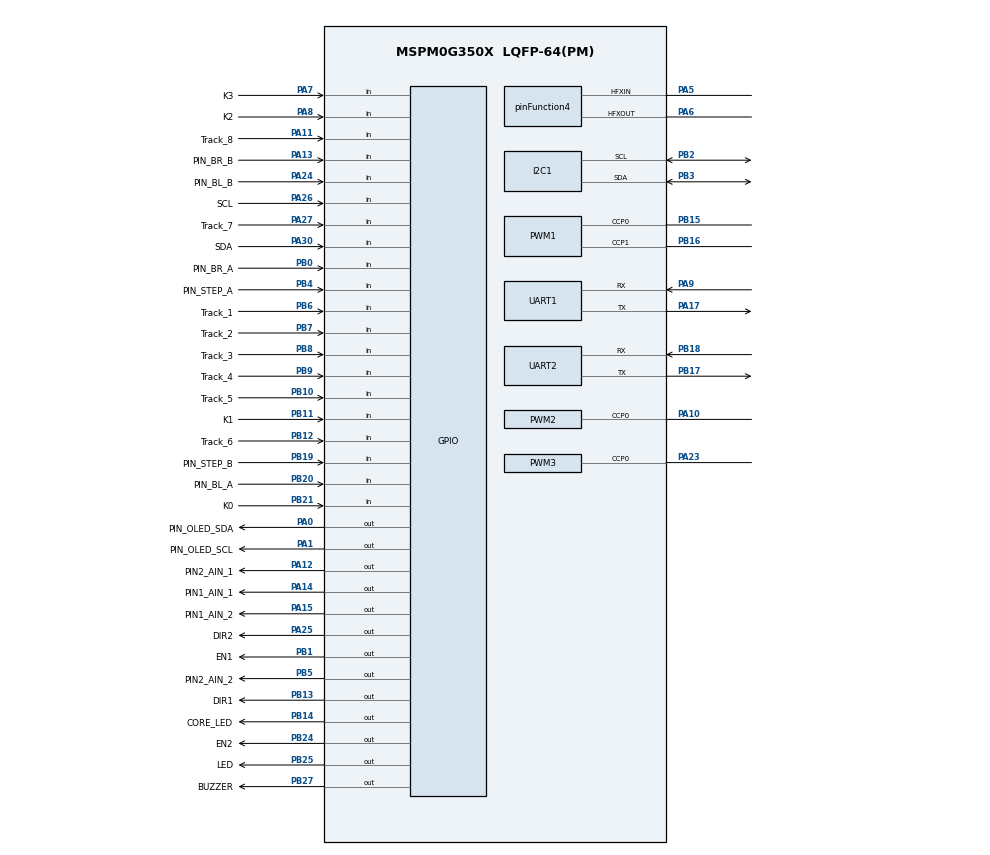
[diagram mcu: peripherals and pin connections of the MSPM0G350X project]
/**
 *
 * @cliArgs --device "MSPM0G350X" --part "Default" --package "LQFP-64(PM)" --product "mspm0_sdk@2.11.00.07"
 * @versions {"tool":"1.28.0+4696"}
 */

/**
 * Import the modules used in this configuration.
 */
const GPIO          = scripting.addModule("/ti/driverlib/GPIO", {}, false);
const GPIO1         = GPIO.addInstance();
const GPIO2         = GPIO.addInstance();
const GPIO3         = GPIO.addInstance();
const GPIO4         = GPIO.addInstance();
const GPIO5         = GPIO.addInstance();
const GPIO6         = GPIO.addInstance();
const GPIO7         = GPIO.addInstance();
const GPIO8         = GPIO.addInstance();
const GPIO9         = GPIO.addInstance();
const GPIO10        = GPIO.addInstance();
const GPIO11        = GPIO.addInstance();
const GPIO12        = GPIO.addInstance();
const I2C           = scripting.addModule("/ti/driverlib/I2C", {}, false);
const I2C1          = I2C.addInstance();
const PWM           = scripting.addModule("/ti/driverlib/PWM", {}, false);
const PWM1          = PWM.addInstance();
const PWM2          = PWM.addInstance();
const PWM3          = PWM.addInstance();
const SYSCTL        = scripting.addModule("/ti/driverlib/SYSCTL");
const SYSTICK       = scripting.addModule("/ti/driverlib/SYSTICK");
const TIMER         = scripting.addModule("/ti/driverlib/TIMER", {}, false);
const TIMER1        = TIMER.addInstance();
const TIMER2        = TIMER.addInstance();
const TIMER3        = TIMER.addInstance();
const UART          = scripting.addModule("/ti/driverlib/UART", {}, false);
const UART1         = UART.addInstance();
const UART2         = UART.addInstance();
const ProjectConfig = scripting.addModule("/ti/project_config/ProjectConfig");

/**
 * Write custom configuration values to the imported modules.
 */
const divider6       = system.clockTree["PLL_CLK2X_DIV"];
divider6.divideValue = 4;

const divider7       = system.clockTree["PLL_PDIV"];
divider7.divideValue = 2;

const divider9       = system.clockTree["UDIV"];
divider9.divideValue = 2;

const multiplier2         = system.clockTree["PLL_QDIV"];
multiplier2.multiplyValue = 8;

const mux4       = system.clockTree["EXHFMUX"];
mux4.inputSelect = "EXHFMUX_XTAL";

const mux8       = system.clockTree["HSCLKMUX"];
mux8.inputSelect = "HSCLKMUX_SYSPLL2X";

const mux12       = system.clockTree["SYSPLLMUX"];
mux12.inputSelect = "zSYSPLLMUX_HFCLK";

const pinFunction4                        = system.clockTree["HFXT"];
pinFunction4.enable                       = true;
pinFunction4.inputFreq                    = 40;
pinFunction4.HFXTStartup                  = 10;
pinFunction4.HFCLKMonitor                 = true;
pinFunction4.peripheral.hfxInPin.$assign  = "PA5";
pinFunction4.peripheral.hfxOutPin.$assign = "PA6";

GPIO1.$name                         = "GPIO_CORE_LED";
GPIO1.associatedPins[0].$name       = "CORE_LED";
GPIO1.associatedPins[0].pin.$assign = "PB14";

const Board = scripting.addModule("/ti/driverlib/Board", {}, false);

GPIO2.$name                         = "GPIO_OLED";
GPIO2.associatedPins.create(2);
GPIO2.associatedPins[0].$name       = "PIN_OLED_SCL";
GPIO2.associatedPins[0].pin.$assign = "PA1";
GPIO2.associatedPins[1].$name       = "PIN_OLED_SDA";
GPIO2.associatedPins[1].pin.$assign = "PA0";

GPIO3.$name                              = "GPIO_KEYS";
GPIO3.associatedPins.create(4);
GPIO3.associatedPins[0].$name            = "K0";
GPIO3.associatedPins[0].direction        = "INPUT";
GPIO3.associatedPins[0].internalResistor = "PULL_UP";
GPIO3.associatedPins[0].pin.$assign      = "PB21";
GPIO3.associatedPins[1].$name            = "K1";
GPIO3.associatedPins[1].direction        = "INPUT";
GPIO3.associatedPins[1].internalResistor = "PULL_UP";
GPIO3.associatedPins[1].pin.$assign      = "PB11";
GPIO3.associatedPins[2].$name            = "K2";
GPIO3.associatedPins[2].direction        = "INPUT";
GPIO3.associatedPins[2].internalResistor = "PULL_UP";
GPIO3.associatedPins[2].pin.$assign      = "PA8";
GPIO3.associatedPins[3].$name            = "K3";
GPIO3.associatedPins[3].direction        = "INPUT";
GPIO3.associatedPins[3].internalResistor = "PULL_UP";
GPIO3.associatedPins[3].pin.$assign      = "PA7";

GPIO4.$name                         = "GPIO_LED_BUZZER";
GPIO4.associatedPins.create(2);
GPIO4.associatedPins[0].$name       = "LED";
GPIO4.associatedPins[0].pin.$assign = "PB25";
GPIO4.associatedPins[1].$name       = "BUZZER";
GPIO4.associatedPins[1].pin.$assign = "PB27";

GPIO5.$name                         = "GPIO_AT24";
GPIO5.associatedPins.create(2);
GPIO5.associatedPins[0].$name       = "SCL";
GPIO5.associatedPins[0].direction   = "INPUT";
GPIO5.associatedPins[0].pin.$assign = "PA26";
GPIO5.associatedPins[1].$name       = "SDA";
GPIO5.associatedPins[1].direction   = "INPUT";
GPIO5.associatedPins[1].pin.$assign = "PA30";

GPIO6.$name                         = "GPIO_MOTOR_1";
GPIO6.associatedPins.create(2);
GPIO6.associatedPins[0].$name       = "PIN1_AIN_1";
GPIO6.associatedPins[0].pin.$assign = "PA14";
GPIO6.associatedPins[1].$name       = "PIN1_AIN_2";
GPIO6.associatedPins[1].pin.$assign = "PA15";

GPIO7.$name                         = "GPIO_MOTOR_2";
GPIO7.associatedPins.create(2);
GPIO7.associatedPins[0].$name       = "PIN2_AIN_1";
GPIO7.associatedPins[0].pin.$assign = "PA12";
GPIO7.associatedPins[1].$name       = "PIN2_AIN_2";
GPIO7.associatedPins[1].pin.$assign = "PB5";

GPIO8.$name                         = "GPIO_ENCODER_BL";
GPIO8.associatedPins.create(2);
GPIO8.associatedPins[0].$name       = "PIN_BL_A";
GPIO8.associatedPins[0].direction   = "INPUT";
GPIO8.associatedPins[0].interruptEn = true;
GPIO8.associatedPins[0].polarity    = "RISE";
GPIO8.associatedPins[0].pin.$assign = "PB20";
GPIO8.associatedPins[1].$name       = "PIN_BL_B";
GPIO8.associatedPins[1].direction   = "INPUT";
GPIO8.associatedPins[1].pin.$assign = "PA24";

GPIO9.$name                         = "GPIO_ENCODER_BR";
GPIO9.associatedPins.create(2);
GPIO9.associatedPins[0].$name       = "PIN_BR_A";
GPIO9.associatedPins[0].direction   = "INPUT";
GPIO9.associatedPins[0].interruptEn = true;
GPIO9.associatedPins[0].polarity    = "RISE";
GPIO9.associatedPins[0].pin.$assign = "PB0";
GPIO9.associatedPins[1].$name       = "PIN_BR_B";
GPIO9.associatedPins[1].direction   = "INPUT";
GPIO9.associatedPins[1].pin.$assign = "PA13";

GPIO10.$name                         = "GPIO_STEP_MOTOR";
GPIO10.associatedPins.create(4);
GPIO10.associatedPins[0].$name       = "DIR1";
GPIO10.associatedPins[0].pin.$assign = "PB13";
GPIO10.associatedPins[1].$name       = "DIR2";
GPIO10.associatedPins[1].pin.$assign = "PA25";
GPIO10.associatedPins[2].$name       = "EN1";
GPIO10.associatedPins[2].pin.$assign = "PB1";
GPIO10.associatedPins[3].$name       = "EN2";
GPIO10.associatedPins[3].pin.$assign = "PB24";

GPIO11.$name                              = "GPIO_Track";
GPIO11.associatedPins.create(8);
GPIO11.associatedPins[0].$name            = "Track_1";
GPIO11.associatedPins[0].direction        = "INPUT";
GPIO11.associatedPins[0].internalResistor = "PULL_UP";
GPIO11.associatedPins[0].pin.$assign      = "PB6";
GPIO11.associatedPins[1].$name            = "Track_2";
GPIO11.associatedPins[1].direction        = "INPUT";
GPIO11.associatedPins[1].internalResistor = "PULL_UP";
GPIO11.associatedPins[1].pin.$assign      = "PB7";
GPIO11.associatedPins[2].$name            = "Track_3";
GPIO11.associatedPins[2].direction        = "INPUT";
GPIO11.associatedPins[2].internalResistor = "PULL_UP";
GPIO11.associatedPins[2].pin.$assign      = "PB8";
GPIO11.associatedPins[3].$name            = "Track_4";
GPIO11.associatedPins[3].direction        = "INPUT";
GPIO11.associatedPins[3].internalResistor = "PULL_UP";
GPIO11.associatedPins[3].pin.$assign      = "PB9";
GPIO11.associatedPins[4].$name            = "Track_5";
GPIO11.associatedPins[4].direction        = "INPUT";
GPIO11.associatedPins[4].internalResistor = "PULL_UP";
GPIO11.associatedPins[4].pin.$assign      = "PB10";
GPIO11.associatedPins[5].$name            = "Track_6";
GPIO11.associatedPins[5].direction        = "INPUT";
GPIO11.associatedPins[5].internalResistor = "PULL_UP";
GPIO11.associatedPins[5].pin.$assign      = "PB12";
GPIO11.associatedPins[6].$name            = "Track_7";
GPIO11.associatedPins[6].direction        = "INPUT";
GPIO11.associatedPins[6].internalResistor = "PULL_UP";
GPIO11.associatedPins[6].pin.$assign      = "PA27";
GPIO11.associatedPins[7].$name            = "Track_8";
GPIO11.associatedPins[7].direction        = "INPUT";
GPIO11.associatedPins[7].internalResistor = "PULL_UP";
GPIO11.associatedPins[7].pin.$assign      = "PA11";

GPIO12.$name                         = "GPIO_ENCODER_STEP";
GPIO12.associatedPins.create(2);
GPIO12.associatedPins[0].$name       = "PIN_STEP_A";
GPIO12.associatedPins[0].direction   = "INPUT";
GPIO12.associatedPins[0].interruptEn = true;
GPIO12.associatedPins[0].polarity    = "RISE";
GPIO12.associatedPins[0].pin.$assign = "PB4";
GPIO12.associatedPins[1].$name       = "PIN_STEP_B";
GPIO12.associatedPins[1].direction   = "INPUT";
GPIO12.associatedPins[1].pin.$assign = "PB19";

I2C1.$name                             = "I2C_IMU";
I2C1.basicEnableController             = true;
I2C1.basicControllerStandardBusSpeed   = "Fast";
I2C1.peripheral.$assign                = "I2C1";
I2C1.peripheral.sdaPin.$assign         = "PB3";
I2C1.peripheral.sclPin.$assign         = "PB2";
I2C1.sdaPinConfig.$name                = "ti_driverlib_gpio_GPIOPinGeneric0";
I2C1.sdaPinConfig.hideOutputInversion  = scripting.forceWrite(false);
I2C1.sdaPinConfig.onlyInternalResistor = scripting.forceWrite(false);
I2C1.sdaPinConfig.passedPeripheralType = scripting.forceWrite("Digital");
I2C1.sclPinConfig.$name                = "ti_driverlib_gpio_GPIOPinGeneric1";
I2C1.sclPinConfig.hideOutputInversion  = scripting.forceWrite(false);
I2C1.sclPinConfig.onlyInternalResistor = scripting.forceWrite(false);
I2C1.sclPinConfig.passedPeripheralType = scripting.forceWrite("Digital");

PWM1.$name                              = "PWM_MOTOR";
PWM1.pwmMode                            = "EDGE_ALIGN_UP";
PWM1.peripheral.$assign                 = "TIMG8";
PWM1.peripheral.ccp0Pin.$assign         = "PB15";
PWM1.peripheral.ccp1Pin.$assign         = "PB16";
PWM1.PWM_CHANNEL_0.$name                = "ti_driverlib_pwm_PWMTimerCC1";
PWM1.PWM_CHANNEL_1.$name                = "ti_driverlib_pwm_PWMTimerCC0";
PWM1.ccp0PinConfig.direction            = scripting.forceWrite("OUTPUT");
PWM1.ccp0PinConfig.hideOutputInversion  = scripting.forceWrite(false);
PWM1.ccp0PinConfig.onlyInternalResistor = scripting.forceWrite(false);
PWM1.ccp0PinConfig.passedPeripheralType = scripting.forceWrite("Digital");
PWM1.ccp0PinConfig.$name                = "ti_driverlib_gpio_GPIOPinGeneric7";
PWM1.ccp1PinConfig.direction            = scripting.forceWrite("OUTPUT");
PWM1.ccp1PinConfig.hideOutputInversion  = scripting.forceWrite(false);
PWM1.ccp1PinConfig.onlyInternalResistor = scripting.forceWrite(false);
PWM1.ccp1PinConfig.passedPeripheralType = scripting.forceWrite("Digital");
PWM1.ccp1PinConfig.$name                = "ti_driverlib_gpio_GPIOPinGeneric6";

PWM2.$name                              = "STEP_MOTOR_1";
PWM2.clockPrescale                      = 8;
PWM2.timerCount                         = 5000;
PWM2.timerStartTimer                    = true;
PWM2.ccIndex                            = [0];
PWM2.interrupts                         = ["CC0_DN_EVENT"];
PWM2.PWM_CHANNEL_0.$name                = "ti_driverlib_pwm_PWMTimerCC2";
PWM2.ccp0PinConfig.direction            = scripting.forceWrite("OUTPUT");
PWM2.ccp0PinConfig.hideOutputInversion  = scripting.forceWrite(false);
PWM2.ccp0PinConfig.onlyInternalResistor = scripting.forceWrite(false);
PWM2.ccp0PinConfig.passedPeripheralType = scripting.forceWrite("Digital");
PWM2.ccp0PinConfig.$name                = "ti_driverlib_gpio_GPIOPinGeneric8";
PWM2.peripheral.$assign                 = "TIMA1";
PWM2.peripheral.ccp0Pin.$assign         = "PA10";

PWM3.$name                              = "STEP_MOTOR_2";
PWM3.clockPrescale                      = 8;
PWM3.timerCount                         = 5000;
PWM3.timerStartTimer                    = true;
PWM3.ccIndex                            = [0];
PWM3.interrupts                         = ["CC0_DN_EVENT"];
PWM3.PWM_CHANNEL_0.$name                = "ti_driverlib_pwm_PWMTimerCC3";
PWM3.ccp0PinConfig.direction            = scripting.forceWrite("OUTPUT");
PWM3.ccp0PinConfig.hideOutputInversion  = scripting.forceWrite(false);
PWM3.ccp0PinConfig.onlyInternalResistor = scripting.forceWrite(false);
PWM3.ccp0PinConfig.passedPeripheralType = scripting.forceWrite("Digital");
PWM3.ccp0PinConfig.$name                = "ti_driverlib_gpio_GPIOPinGeneric9";
PWM3.peripheral.$assign                 = "TIMG7";
PWM3.peripheral.ccp0Pin.$assign         = "PA23";

SYSCTL.forceDefaultClkConfig = true;
SYSCTL.clockTreeEn           = true;

SYSTICK.periodEnable    = true;
SYSTICK.interruptEnable = true;
SYSTICK.systickEnable   = true;
SYSTICK.period          = 80000;

TIMER1.$name              = "TIMER_ATT";
TIMER1.timerMode          = "PERIODIC";
TIMER1.timerPeriod        = "5 ms";
TIMER1.timerClkPrescale   = 8;
TIMER1.interrupts         = ["ZERO"];
TIMER1.interruptPriority  = "2";
TIMER1.peripheral.$assign = "TIMG0";

TIMER2.$name              = "TIMER_0";
TIMER2.timerMode          = "PERIODIC";
TIMER2.timerPeriod        = "10 ms";
TIMER2.timerClkPrescale   = 100;
TIMER2.interrupts         = ["ZERO"];
TIMER2.interruptPriority  = "1";
TIMER2.peripheral.$assign = "TIMA0";

TIMER3.$name              = "TIMER_BALL";
TIMER3.timerClkPrescale   = 100;
TIMER3.timerMode          = "PERIODIC";
TIMER3.timerPeriod        = "10 ms";
TIMER3.interrupts         = ["ZERO"];
TIMER3.interruptPriority  = "2";
TIMER3.peripheral.$assign = "TIMG6";

UART1.$name                            = "UART_Cam";
UART1.targetBaudRate                   = 115200;
UART1.enabledInterrupts                = ["RX"];
UART1.peripheral.$assign               = "UART1";
UART1.peripheral.rxPin.$assign         = "PA9";
UART1.peripheral.txPin.$assign         = "PA17";
UART1.txPinConfig.direction            = scripting.forceWrite("OUTPUT");
UART1.txPinConfig.hideOutputInversion  = scripting.forceWrite(false);
UART1.txPinConfig.onlyInternalResistor = scripting.forceWrite(false);
UART1.txPinConfig.passedPeripheralType = scripting.forceWrite("Digital");
UART1.txPinConfig.$name                = "ti_driverlib_gpio_GPIOPinGeneric2";
UART1.rxPinConfig.hideOutputInversion  = scripting.forceWrite(false);
UART1.rxPinConfig.onlyInternalResistor = scripting.forceWrite(false);
UART1.rxPinConfig.passedPeripheralType = scripting.forceWrite("Digital");
UART1.rxPinConfig.$name                = "ti_driverlib_gpio_GPIOPinGeneric3";

UART2.$name                            = "UART_Communicate";
UART2.targetBaudRate                   = 115200;
UART2.enabledInterrupts                = ["RX"];
UART2.peripheral.$assign               = "UART2";
UART2.peripheral.rxPin.$assign         = "PB18";
UART2.peripheral.txPin.$assign         = "PB17";
UART2.txPinConfig.direction            = scripting.forceWrite("OUTPUT");
UART2.txPinConfig.hideOutputInversion  = scripting.forceWrite(false);
UART2.txPinConfig.onlyInternalResistor = scripting.forceWrite(false);
UART2.txPinConfig.passedPeripheralType = scripting.forceWrite("Digital");
UART2.txPinConfig.$name                = "ti_driverlib_gpio_GPIOPinGeneric4";
UART2.rxPinConfig.hideOutputInversion  = scripting.forceWrite(false);
UART2.rxPinConfig.onlyInternalResistor = scripting.forceWrite(false);
UART2.rxPinConfig.passedPeripheralType = scripting.forceWrite("Digital");
UART2.rxPinConfig.$name                = "ti_driverlib_gpio_GPIOPinGeneric5";

ProjectConfig.deviceSpin = "MSPM0G3507";

/**
 * Pinmux solution for unlocked pins/peripherals. This ensures that minor changes to the automatic solver in a future
 * version of the tool will not impact the pinmux you originally saw.  These lines can be completely deleted in order to
 * re-solve from scratch.
 */
pinFunction4.peripheral.$suggestSolution   = "SYSCTL";
Board.peripheral.$suggestSolution          = "DEBUGSS";
Board.peripheral.swclkPin.$suggestSolution = "PA20";
Board.peripheral.swdioPin.$suggestSolution = "PA19";
